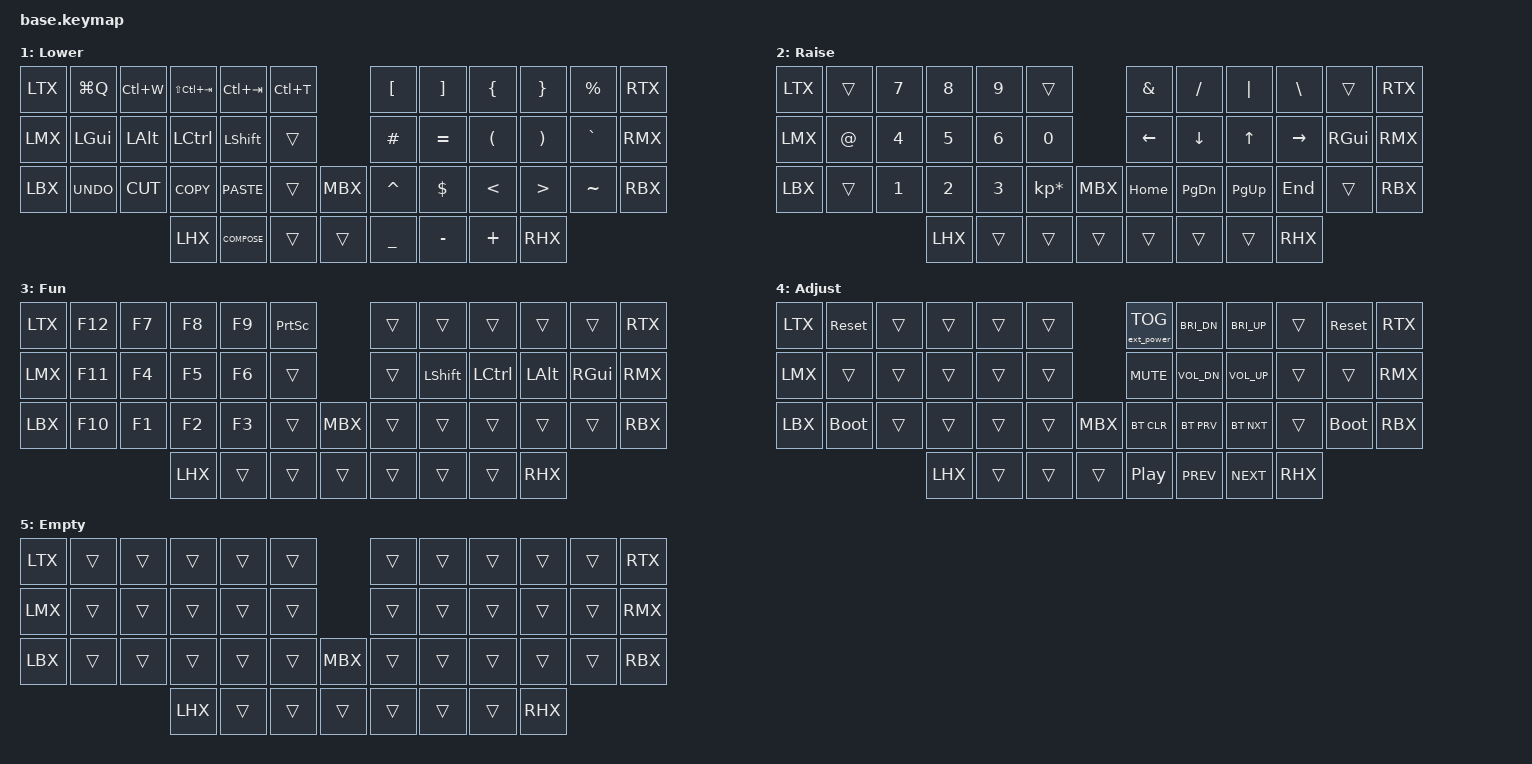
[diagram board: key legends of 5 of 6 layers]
#include <behaviors.dtsi>
#include <dt-bindings/zmk/keys.h>
#include <dt-bindings/zmk/bt.h>
#include <dt-bindings/zmk/ext_power.h>

#define BASE  0
#define LOWER 1
#define RAISE 2
#define FUN   3
#define ADJUST 4

#include "keys/base.h"
#include "includes/macros.dtsi"
#include "includes/mods.dtsi"
#include "includes/dance.dtsi"
#include "includes/combos.dtsi"
#include "includes/morphs.dtsi"
#include "includes/settings.dtsi"

#define MEH LC(LS(LALT))
#define CUT LS(DEL)
#define COPY LC(INS)
#define PASTE LS(INS)
#define COMPOSE K_CMENU

/ {
 
  keymap {
    compatible = "zmk,keymap";

    base_layer {
      display-name = "Base";
      bindings = <
//    ╭───┬─────────────┬─────────────┬──────────────┬──────────────┬───────────────╮                                  ╭────────────────┬──────────────┬──────────────┬─────────────┬──────────────┬───╮
//    │   │      Q      │      W      │  &hml MEH E  │      R       │       T       │                                  │       Y        │      U       │  &hmr MEH I  │      O      │      P       │   │
//    ├───┼─────────────┼─────────────┼──────────────┼──────────────┼───────────────┤                                  ├────────────────┼──────────────┼──────────────┼─────────────┼──────────────┼───┤
//    │   │ &hml LGUI A │ &hml LALT S │ &hml LCTRL D │ &hml LSHFT F │       G       │                                  │       H        │ &hmr LSHFT J │ &hmr LCTRL K │ &hmr LALT L │ &hmr RGUI '  │   │
//    ├───┼─────────────┼─────────────┼──────────────┼──────────────┼───────────────┼──────────────────────────────────┼────────────────┼──────────────┼──────────────┼─────────────┼──────────────┼───┤
//    │   │      Z      │      X      │      C       │      V       │       B       │                                  │       N        │      M       │ &comma_morph │ &dot_morph  │ &qmark_morph │   │
//    ╰───┴─────────────┴─────────────┼──────────────┼──────────────┼───────────────┼────────────────┬─────────────────┼────────────────┼──────────────┼──────────────┼─────────────┴──────────────┴───╯
//                                    │              │ &tm LGUI TAB │ &lt LOWER ESC │ &lt ADJUST RET │ &tm RSHFT SPACE │ &lt RAISE BSPC │ &lt FUN DEL  │              │                                 
//                                    ╰──────────────┴──────────────┴───────────────┴────────────────┴─────────────────┴────────────────┴──────────────┴──────────────╯                                 
  _LTX   &kp Q         &kp W         &hml MEH E     &kp R          &kp T                                              &kp Y            &kp U          &hmr MEH I     &kp O         &kp P           _RTX
  _LMX   &hml LGUI A   &hml LALT S   &hml LCTRL D   &hml LSHFT F   &kp G                                              &kp H            &hmr LSHFT J   &hmr LCTRL K   &hmr LALT L   &hmr RGUI SQT   _RMX
  _LBX   &kp Z         &kp X         &kp C          &kp V          &kp B                         _MBX                 &kp N            &kp M          &comma_morph   &dot_morph    &qmark_morph    _RBX
                                     _LHX           &tm LGUI TAB   &lt LOWER ESC   &lt ADJUST RET   &tm RSHFT SPACE   &lt RAISE BSPC   &lt FUN DEL    _RHX                                             
      >;
      sensor-bindings = <&inc_dec_kp C_VOL_UP C_VOL_DN>;
    };

    lower_layer {
      display-name = "Lower";
      bindings = <
//    ╭───┬──────┬──────┬───────┬───────┬────╮       ╭───┬───┬───┬───┬───┬───╮
//    │   │  ⌘Q  │  ⌃W  │  ⇧⌃⇥  │  ⌃⇥   │ ⌃T │       │ [ │ ] │ { │ } │ % │   │
//    ├───┼──────┼──────┼───────┼───────┼────┤       ├───┼───┼───┼───┼───┼───┤
//    │   │ LGUI │ LALT │ LCTRL │ LSHFT │    │       │ # │ = │ ( │ ) │ ` │   │
//    ├───┼──────┼──────┼───────┼───────┼────┼───────┼───┼───┼───┼───┼───┼───┤
//    │   │  ↩️   │  ✂️   │  📄   │  📋   │    │       │ ^ │ $ │ < │ > │ ~ │   │
//    ╰───┴──────┴──────┼───────┼───────┼────┼───┬───┼───┼───┼───┼───┴───┴───╯
//                      │       │  🌍   │    │   │ _ │ - │ + │   │            
//                      ╰───────┴───────┴────┴───┴───┴───┴───┴───╯            
  _LTX   &kp LG(Q)    &kp LC(W)   &kp LS(LC(TAB))   &kp LC(TAB)   &kp LC(T)                             &kp LBKT    &kp RBKT     &kp LBRC   &kp RBRC   &kp PRCNT   _RTX
  _LMX   &kp LGUI     &kp LALT    &kp LCTRL         &kp LSHFT     &trans                                &kp HASH    &kp EQUAL    &kp LPAR   &kp RPAR   &kp GRAVE   _RMX
  _LBX   &kp K_UNDO   &kp K_CUT     &kp K_COPY          &kp PASTE     &trans               _MBX             &kp CARET   &kp DOLLAR   &kp LT     &kp GT     &kp TILDE   _RBX
                                  _LHX              &kp COMPOSE   &trans      &trans   &kp UNDERSCORE   &kp MINUS   &kp PLUS     _RHX                                  
      >;
      sensor-bindings = <&inc_dec_kp C_VOL_UP C_VOL_DN>;
    };

    raise_layer {
      display-name = "Raise";
      bindings = <
//    ╭───┬───┬───┬───┬───┬───╮       ╭───┬───┬───┬───┬──────┬───╮
//    │   │   │ 7 │ 8 │ 9 │   │       │ & │ / │ | │ \ │      │   │
//    ├───┼───┼───┼───┼───┼───┤       ├───┼───┼───┼───┼──────┼───┤
//    │   │ @ │ 4 │ 5 │ 6 │ 0 │       │ ← │ ↓ │ ↑ │ → │ RGUI │   │
//    ├───┼───┼───┼───┼───┼───┼───────┼───┼───┼───┼───┼──────┼───┤
//    │   │   │ 1 │ 2 │ 3 │ * │       │ ⇱ │ ⇟ │ ⇞ │ ⇲ │      │   │
//    ╰───┴───┴───┼───┼───┼───┼───┬───┼───┼───┼───┼───┴──────┴───╯
//                │   │   │   │   │   │   │   │   │               
//                ╰───┴───┴───┴───┴───┴───┴───┴───╯               
  _LTX   &trans   &kp N7   &kp N8   &kp N9   &trans                              &kp AMPS   &kp FSLH    &kp PIPE    &kp BSLH    &trans     _RTX
  _LMX   &kp AT   &kp N4   &kp N5   &kp N6   &kp N0                              &kp LEFT   &kp DOWN    &kp UP      &kp RIGHT   &kp RGUI   _RMX
  _LBX   &trans   &kp N1   &kp N2   &kp N3   &kp KP_MULTIPLY        _MBX         &kp HOME   &kp PG_DN   &kp PG_UP   &kp END     &trans     _RBX
                           _LHX     &trans   &trans            &trans   &trans   &trans     &trans      _RHX                                   
      >;
      sensor-bindings = <&inc_dec_kp C_VOL_UP C_VOL_DN>;
    };

    fun_layer {
      display-name = "Fun";
      bindings = <
//    ╭───┬─────┬────┬────┬────┬───────╮       ╭───┬───────┬───────┬──────┬──────┬───╮
//    │   │ F12 │ F7 │ F8 │ F9 │ PSCRN │       │   │       │       │      │      │   │
//    ├───┼─────┼────┼────┼────┼───────┤       ├───┼───────┼───────┼──────┼──────┼───┤
//    │   │ F11 │ F4 │ F5 │ F6 │       │       │   │ LSHFT │ LCTRL │ LALT │ RGUI │   │
//    ├───┼─────┼────┼────┼────┼───────┼───────┼───┼───────┼───────┼──────┼──────┼───┤
//    │   │ F10 │ F1 │ F2 │ F3 │       │       │   │       │       │      │      │   │
//    ╰───┴─────┴────┼────┼────┼───────┼───┬───┼───┼───────┼───────┼──────┴──────┴───╯
//                   │    │    │       │   │   │   │       │       │                  
//                   ╰────┴────┴───────┴───┴───┴───┴───────┴───────╯                  
  _LTX   &kp F12   &kp F7   &kp F8   &kp F9   &kp PSCRN                     &trans   &trans      &trans      &trans     &trans     _RTX
  _LMX   &kp F11   &kp F4   &kp F5   &kp F6   &trans                        &trans   &kp LSHFT   &kp LCTRL   &kp LALT   &kp RGUI   _RMX
  _LBX   &kp F10   &kp F1   &kp F2   &kp F3   &trans           _MBX         &trans   &trans      &trans      &trans     &trans     _RBX
                            _LHX     &trans   &trans      &trans   &trans   &trans   &trans      _RHX                                  
      >;
      sensor-bindings = <&inc_dec_kp C_VOL_UP C_VOL_DN>;
    };

    adjust_layer {
      display-name = "Adjust";
      bindings = <
//    ╭───┬────┬───┬───┬───┬───╮       ╭──────┬──────┬──────┬───┬────┬───╮
//    │   │ 🔄 │   │   │   │   │       │  🔌  │  🔅  │  🔆  │   │ 🔄 │   │
//    ├───┼────┼───┼───┼───┼───┤       ├──────┼──────┼──────┼───┼────┼───┤
//    │   │    │   │   │   │   │       │  🔇  │  🔉  │  🔊  │   │    │   │
//    ├───┼────┼───┼───┼───┼───┼───────┼──────┼──────┼──────┼───┼────┼───┤
//    │   │ 💾 │   │   │   │   │       │ 🛜❌ │ 🛜🔽 │ 🛜🔼 │   │ 💾 │   │
//    ╰───┴────┴───┼───┼───┼───┼───┬───┼──────┼──────┼──────┼───┴────┴───╯
//                 │   │   │   │   │ ⏯️ │  ⏮️   │  ⏭️   │      │             
//                 ╰───┴───┴───┴───┴───┴──────┴──────┴──────╯             
  _LTX   &sys_reset    &trans   &trans   &trans   &trans                       &ext_power EP_TOG   &kp C_BRI_DN   &kp C_BRI_UP   &trans   &sys_reset    _RTX
  _LMX   &trans        &trans   &trans   &trans   &trans                       &kp C_MUTE          &kp C_VOL_DN   &kp C_VOL_UP   &trans   &trans        _RMX
  _LBX   &bootloader   &trans   &trans   &trans   &trans         _MBX          &bt BT_CLR          &bt BT_PRV     &bt BT_NXT     &trans   &bootloader   _RBX
                                _LHX     &trans   &trans   &trans   &kp C_PP   &kp C_PREV          &kp C_NEXT     _RHX                                      
      >;
      sensor-bindings = <&inc_dec_kp C_VOL_UP C_VOL_DN>;
    };

    empty_layer {
      display-name = "Empty";
      bindings = <
//    ╭───┬───┬───┬───┬───┬───╮       ╭───┬───┬───┬───┬───┬───╮
//    │   │   │   │   │   │   │       │   │   │   │   │   │   │
//    ├───┼───┼───┼───┼───┼───┤       ├───┼───┼───┼───┼───┼───┤
//    │   │   │   │   │   │   │       │   │   │   │   │   │   │
//    ├───┼───┼───┼───┼───┼───┼───────┼───┼───┼───┼───┼───┼───┤
//    │   │   │   │   │   │   │       │   │   │   │   │   │   │
//    ╰───┴───┴───┼───┼───┼───┼───┬───┼───┼───┼───┼───┴───┴───╯
//                │   │   │   │   │   │   │   │   │            
//                ╰───┴───┴───┴───┴───┴───┴───┴───╯            
  _LTX   &trans   &trans   &trans   &trans   &trans                     &trans   &trans   &trans   &trans   &trans   _RTX
  _LMX   &trans   &trans   &trans   &trans   &trans                     &trans   &trans   &trans   &trans   &trans   _RMX
  _LBX   &trans   &trans   &trans   &trans   &trans        _MBX         &trans   &trans   &trans   &trans   &trans   _RBX
                           _LHX     &trans   &trans   &trans   &trans   &trans   &trans   _RHX                           
      >;
      sensor-bindings = <&inc_dec_kp C_VOL_UP C_VOL_DN>;
    };
  };
};
